# MKE04Z1284 register map
Vendor: Freescale Semiconductor, Inc.; File version: 1.6
CPU: CM0PLUS r0p0, little endian, no MPU, no FPU, 0x2 interrupt priority bits, 0x0 interrupts
Registers are 32-bit, read-write, reset 0x0 unless marked. A register's access mark holds for its fields unless they carry their own. Offsets are from the block's base; [hi:lo] are bit positions; 'fields as' and 'values as' point back to an identical list.

## FTMRE — Flash Memory
Base 0x40020000; register names take the prefix FTMRE_
0x01 FCCOBIX 8-bit — Flash CCOB Index Register
  [2:0] CCOBIX — Common Command Register Index
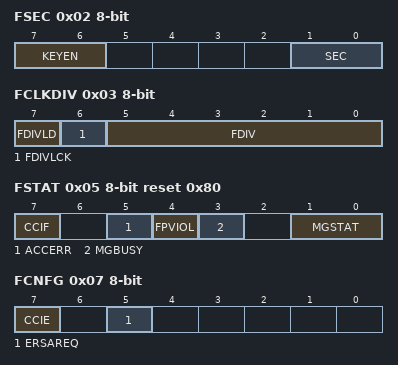
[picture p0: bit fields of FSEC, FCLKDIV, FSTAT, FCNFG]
0x02 FSEC 8-bit ro reset not defined — Flash Security Register
  [7:6] KEYEN — Backdoor Key Security Enable Bits
    0=Disabled; 1=Disabled; 2=Enabled; 3=Disabled
  [1:0] SEC — Flash Security Bits
    0=Secured; 1=Secured; 2=Unsecured; 3=Secured
0x03 FCLKDIV 8-bit — Flash Clock Divider Register
  [7] FDIVLD ro — Clock Divider Loaded
    0=FCLKDIV register has not been written since the last reset; 1=FCLKDIV register has been written since the last reset
  [6] FDIVLCK — Clock Divider Locked
    0=FDIV field is open for writing; 1=FDIV value is locked and cannot be changed. After the lock bit is set high, only reset can clear this bit and restore writability to the FDIV field in user mode.
  [5:0] FDIV — Clock Divider Bits
0x05 FSTAT 8-bit reset 0x80 — Flash Status Register
  [7] CCIF — Command Complete Interrupt Flag
    0=Flash command is in progress; 1=Flash command has completed
  [5] ACCERR — Flash Access Error Flag
    0=No access error is detected; 1=Access error is detected
  [4] FPVIOL — Flash Protection Violation Flag
    0=No protection violation is detected; 1=Protection violation is detected
  [3] MGBUSY ro — Memory Controller Busy Flag
    0=Memory controller is idle; 1=Memory controller is busy executing a flash command (CCIF = 0)
  [1:0] MGSTAT ro — Memory Controller Command Completion Status Flag
0x07 FCNFG 8-bit — Flash Configuration Register
  [7] CCIE — Command Complete Interrupt Enable
    0=Command complete interrupt is disabled; 1=An interrupt will be requested whenever the CCIF flag in the FSTAT register is set
  [5] ERSAREQ ro — Debugger Mass Erase Request
    0=No request or request complete; 1=Request to run the Erase All Blocks command verify the erased state program the security byte in the Flash Configuration Field to the unsecure state release MCU security by setting FSEC[SEC] to the unsecure state
0x08 FCCOBLO 8-bit — Flash Common Command Object Register: Low
  [7:0] CCOB — Common Command Object Bit 7:0
0x09 FCCOBHI 8-bit — Flash Common Command Object Register:High
  [7:0] CCOB — Common Command Object Bit 15:8
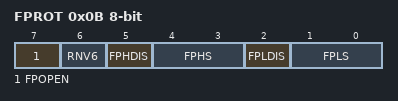
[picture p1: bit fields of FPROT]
0x0B FPROT 8-bit reset not defined — Flash Protection Register
  [7] FPOPEN — Flash Protection Operation Enable
    0=When FPOPEN is clear, the FPHDIS and FPLDIS fields define unprotected address ranges as specified by the corresponding FPHS and FPLS fields; 1=When FPOPEN is set, the FPHDIS and FPLDIS fields enable protection for the address range specified by the corresponding FPHS and FPLS fields
  [6] RNV6 ro — Reserved Nonvolatile Bit
  [5] FPHDIS — Flash Protection Higher Address Range Disable
    0=Protection/Unprotection enabled; 1=Protection/Unprotection disabled
  [4:3] FPHS — Flash Protection Higher Address Size
  [2] FPLDIS — Flash Protection Lower Address Range Disable
    values as FPHDIS
  [1:0] FPLS — Flash Protection Lower Address Size
0x0F FOPT 8-bit ro reset not defined — Flash Option Register
  [7:0] NV — Nonvolatile Bits

## IRQ — Interrupt
Base 0x40031000; register names take the prefix IRQ_
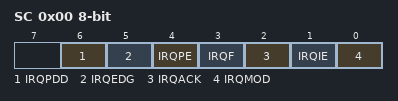
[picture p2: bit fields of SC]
0x00 SC 8-bit — Interrupt Pin Request Status and Control Register
  [6] IRQPDD — Interrupt Request (IRQ) Pull Device Disable
    0=IRQ pull device enabled if IRQPE = 1; 1=IRQ pull device disabled if IRQPE = 1
  [5] IRQEDG — Interrupt Request (IRQ) Edge Select
    0=IRQ is falling-edge or falling-edge/low-level sensitive; 1=IRQ is rising-edge or rising-edge/high-level sensitive
  [4] IRQPE — IRQ Pin Enable
    0=IRQ pin function is disabled; 1=IRQ pin function is enabled
  [3] IRQF ro — IRQ Flag
    0=No IRQ request; 1=IRQ event is detected
  [2] IRQACK wo — IRQ Acknowledge
  [1] IRQIE — IRQ Interrupt Enable
    0=Interrupt request when IRQF set is disabled (use polling); 1=Interrupt requested whenever IRQF = 1
  [0] IRQMOD — IRQ Detection Mode
    0=IRQ event is detected only on falling/rising edges; 1=IRQ event is detected on falling/rising edges and low/high levels
